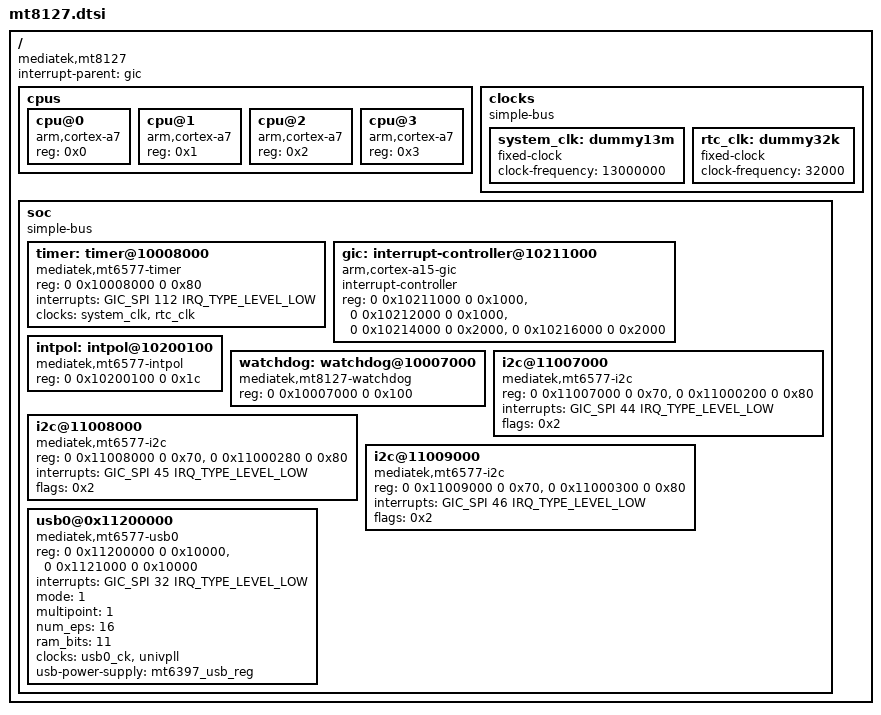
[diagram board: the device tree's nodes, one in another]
/*
 * Copyright (c) 2014 MundoReader S.L.
 * Author: Matthias Brugger <matthias.bgg@gmail.com>
 *
 * This program is free software; you can redistribute it and/or modify
 * it under the terms of the GNU General Public License as published by
 * the Free Software Foundation; either version 2 of the License, or
 * (at your option) any later version.
 *
 * This program is distributed in the hope that it will be useful,
 * but WITHOUT ANY WARRANTY; without even the implied warranty of
 * MERCHANTABILITY or FITNESS FOR A PARTICULAR PURPOSE.  See the
 * GNU General Public License for more details.
 */

#include <dt-bindings/interrupt-controller/irq.h>
#include <dt-bindings/interrupt-controller/arm-gic.h>
#include "skeleton64.dtsi"

/ {
	compatible = "mediatek,mt8127";
	interrupt-parent = <&gic>;

	cpus {
		#address-cells = <1>;
		#size-cells = <0>;

		cpu@0 {
			device_type = "cpu";
			compatible = "arm,cortex-a7";
			reg = <0x0>;
		};
		cpu@1 {
			device_type = "cpu";
			compatible = "arm,cortex-a7";
			reg = <0x1>;
		};
		cpu@2 {
			device_type = "cpu";
			compatible = "arm,cortex-a7";
			reg = <0x2>;
		};
		cpu@3 {
			device_type = "cpu";
			compatible = "arm,cortex-a7";
			reg = <0x3>;
		};

	};

	clocks {
		#address-cells = <1>;
		#size-cells = <1>;
		compatible = "simple-bus";
		ranges;

		system_clk: dummy13m {
			compatible = "fixed-clock";
			clock-frequency = <13000000>;
			#clock-cells = <0>;
		};

		rtc_clk: dummy32k {
			compatible = "fixed-clock";
			clock-frequency = <32000>;
			#clock-cells = <0>;
		};
	};

	soc {
		#address-cells = <2>;
		#size-cells = <2>;
		compatible = "simple-bus";
		ranges;

		timer: timer@10008000 {
			compatible = "mediatek,mt6577-timer";
			reg = <0 0x10008000 0 0x80>;
			interrupts = <GIC_SPI 112 IRQ_TYPE_LEVEL_LOW>;
			clocks = <&system_clk>, <&rtc_clk>;
			clock-names = "system-clk", "rtc-clk";
		};

		gic: interrupt-controller@10211000 {
			compatible = "arm,cortex-a15-gic";
			interrupt-controller;
			#interrupt-cells = <3>;
			reg = <0 0x10211000 0 0x1000>,
			      <0 0x10212000 0 0x1000>,
			      <0 0x10214000 0 0x2000>,
			      <0 0x10216000 0 0x2000>;
		};

		intpol: intpol@10200100 {
			compatible = "mediatek,mt6577-intpol";
			reg = <0 0x10200100 0 0x1c>;
		};

		watchdog: watchdog@10007000 {
			compatible = "mediatek,mt8127-watchdog","mediatek,mt6577-watchdog";
			reg = <0 0x10007000 0 0x100>;
		};

		i2c@11007000 {
			compatible = "mediatek,mt6577-i2c";
			reg = <0 0x11007000 0 0x70>,
			      <0 0x11000200 0 0x80>;
			interrupts = <GIC_SPI 44 IRQ_TYPE_LEVEL_LOW>;
			flags = <0x2>;
		};

		i2c@11008000 {
			compatible = "mediatek,mt6577-i2c";
			reg = <0 0x11008000 0 0x70>,
			      <0 0x11000280 0 0x80>;
			interrupts = <GIC_SPI 45 IRQ_TYPE_LEVEL_LOW>;
			flags = <0x2>;
		};

		i2c@11009000 {
			compatible = "mediatek,mt6577-i2c";
			reg = <0 0x11009000 0 0x70>,
			      <0 0x11000300 0 0x80>;
			interrupts = <GIC_SPI 46 IRQ_TYPE_LEVEL_LOW>;
			flags = <0x2>;
		};

		usb0@0x11200000 {
			compatible = "mediatek,mt6577-usb0";
			reg = <0 0x11200000 0 0x10000>,
				  <0 0x1121000 0 0x10000>;
			interrupts = <GIC_SPI 32 IRQ_TYPE_LEVEL_LOW>;
			mode = <1>;
			multipoint = <1>;
			num_eps = <16>;
			ram_bits = <11>;
			clocks =<&usb0_ck>, <&univpll>;
			clock-names = "usb0_clk_main", "univpll_clk";
			usb-power-supply = <&mt6397_usb_reg>;
		};

	};
};
